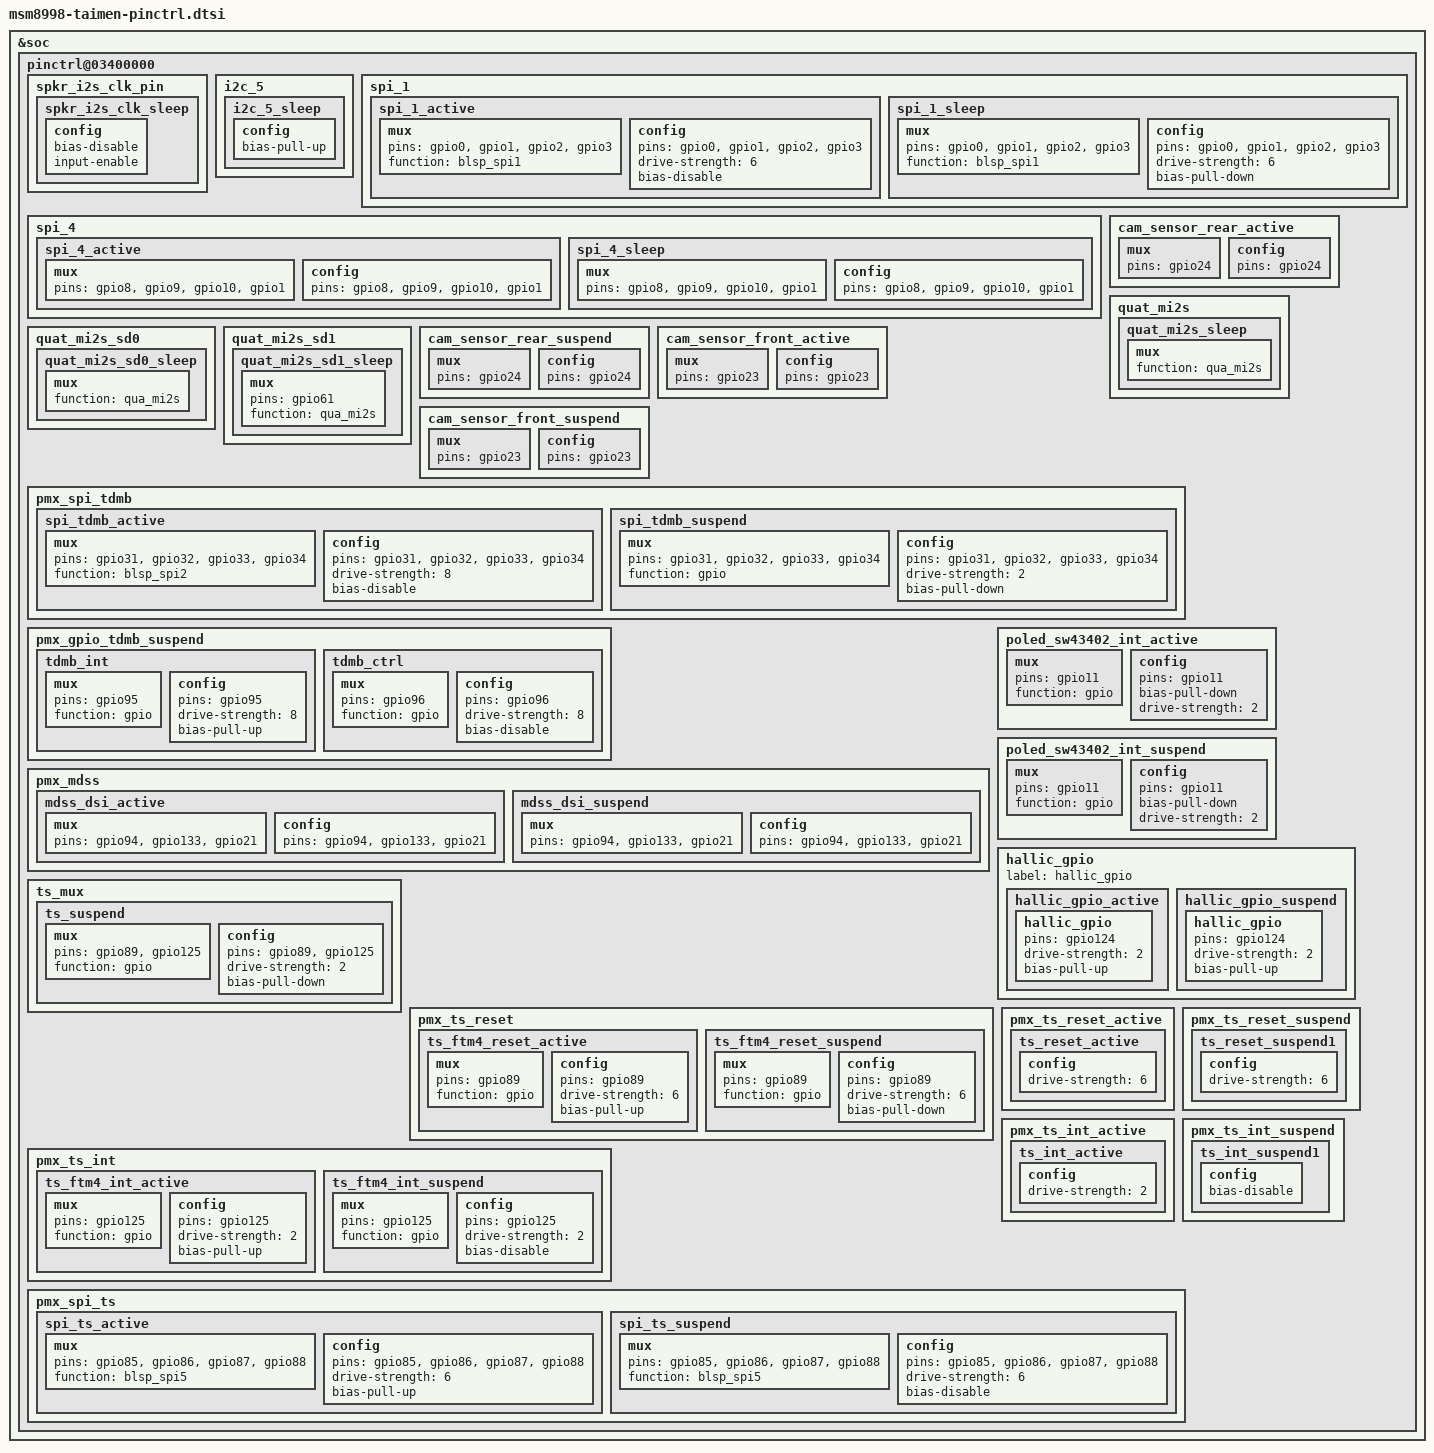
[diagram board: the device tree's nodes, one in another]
/* Copyright (c) 2017, The Linux Foundation. All rights reserved.
 *
 * This program is free software; you can redistribute it and/or modify
 * it under the terms of the GNU General Public License version 2 and
 * only version 2 as published by the Free Software Foundation.
 *
 * This program is distributed in the hope that it will be useful,
 * but WITHOUT ANY WARRANTY; without even the implied warranty of
 * MERCHANTABILITY or FITNESS FOR A PARTICULAR PURPOSE.  See the
 * GNU General Public License for more details.
 */

&soc {
	pinctrl@03400000 {
		spkr_i2s_clk_pin {
			spkr_i2s_clk_sleep {
				config {
					bias-disable;
					input-enable;
				};
			};
		};

		i2c_5 {
			i2c_5_sleep {
				config {
					bias-pull-up;
				};
			};
		};

		/* SPI CONFIGURATION */

		spi_1 {
			spi_1_active {
				mux {
					pins = "gpio0", "gpio1",
							"gpio2", "gpio3";
					function = "blsp_spi1";
				};

				config {
					pins = "gpio0", "gpio1",
							"gpio2", "gpio3";
					drive-strength = <6>;
					bias-disable;
				};
			};

			spi_1_sleep {
				mux {
					pins = "gpio0", "gpio1",
							"gpio2", "gpio3";
					function = "blsp_spi1";
				};

				config {
					pins = "gpio0", "gpio1",
							"gpio2", "gpio3";
					drive-strength = <6>;
					bias-pull-down;
				};
			};
		};

		spi_4 {
			spi_4_active {
				mux {
					pins = "gpio8", "gpio9",
							"gpio10", "gpio1";
				};

				config {
					pins = "gpio8", "gpio9",
							"gpio10", "gpio1";
				};
			};

			spi_4_sleep {
				mux {
					pins = "gpio8", "gpio9",
							"gpio10", "gpio1";
				};

				config {
					pins = "gpio8", "gpio9",
							"gpio10", "gpio1";
				};
			};
		};

		cam_sensor_rear_active {
			/* RESET, STANDBY */
			mux {
				pins = "gpio24";
			};

			config {
				pins = "gpio24";
			};
		};

		/* tas2557s MI2S Setting */
		quat_mi2s {
			quat_mi2s_sleep {
				mux {
					function = "qua_mi2s";
				};
			};
		};

		quat_mi2s_sd0 {
			quat_mi2s_sd0_sleep {
				mux {
					function = "qua_mi2s";
				};
			};
		};

		quat_mi2s_sd1 {
			quat_mi2s_sd1_sleep {
				mux {
					pins = "gpio61";
					function = "qua_mi2s";
				};
			};
		};

		cam_sensor_rear_suspend {
			/* RESET, STANDBY */
			mux {
				pins = "gpio24";
			};

			config {
				pins = "gpio24";
			};
		};

		cam_sensor_front_active {
			/* RESET */
			mux {
				pins = "gpio23";
			};

			config {
				pins = "gpio23";
			};
		};

		cam_sensor_front_suspend {
			/* RESET */
			mux {
				pins = "gpio23";
			};

			config {
				pins = "gpio23";
			};
		};

		pmx_spi_tdmb {
			spi_tdmb_active {
				mux {
					pins =  "gpio31", "gpio32", "gpio33", "gpio34";
					function = "blsp_spi2";
				};

				config {
					pins =  "gpio31", "gpio32", "gpio33", "gpio34";
					drive-strength = <8>;
					bias-disable;
				};
			};

			spi_tdmb_suspend {
				mux {
					pins =  "gpio31", "gpio32", "gpio33", "gpio34";
					function = "gpio";
				};

				config {
					pins =  "gpio31", "gpio32", "gpio33", "gpio34";
					drive-strength = <2>;
					bias-pull-down;
				};
			};
		};

		pmx_gpio_tdmb_suspend {
			tdmb_int {
				mux {
					pins = "gpio95";
					function = "gpio";
				};
				config {
					pins = "gpio95";
					drive-strength = <8>;
					bias-pull-up;
				};
			};
			tdmb_ctrl {
				mux {
					pins = "gpio96";
					function = "gpio";
				};
				config {
					pins = "gpio96";
					drive-strength = <8>;
					bias-disable;
				};
			};
		};

		pmx_mdss {
			mdss_dsi_active {
				mux {
					pins = "gpio94", "gpio133", "gpio21";
				};

				config {
					pins = "gpio94", "gpio133", "gpio21";
				};
			};
			mdss_dsi_suspend {
				mux {
					pins = "gpio94", "gpio133", "gpio21";
				};

				config {
					pins = "gpio94", "gpio133", "gpio21";
				};
			};
		};
		poled_sw43402_int_active {
			mux {
				pins = "gpio11";
				function = "gpio";
			};

			config {
				pins = "gpio11";
				bias-pull-down;
				drive-strength = <2>;
			};
		};

		poled_sw43402_int_suspend {
			mux {
				pins = "gpio11";
				function = "gpio";
			};

			config {
				pins = "gpio11";
				bias-pull-down;
				drive-strength = <2>;
			};
		};

		/* pin set for Hall IC */
		hallic_gpio {
			label = "hallic_gpio";
			hallic_gpio_active: hallic_gpio_active {
				hallic_gpio {
					pins = "gpio124";
					drive-strength = <2>;
					bias-pull-up;
				};
			};
			hallic_gpio_suspend: hallic_gpio_suspend {
				hallic_gpio {
					pins = "gpio124";
					drive-strength = <2>;
					bias-pull-up;
				};
			};
		};

		ts_mux {
			ts_suspend: ts_suspend {
				mux {
					pins = "gpio89", "gpio125";
					function = "gpio";
				};

				config {
					pins = "gpio89", "gpio125";
					drive-strength = <2>;
					bias-pull-down;
				};
			};
		};

		pmx_ts_reset {
			ts_ftm4_reset_active {
				mux {
					pins = "gpio89";
					function = "gpio";
				};
				config {
					pins = "gpio89";
					drive-strength = <6>;
					bias-pull-up;
				};
			};

			ts_ftm4_reset_suspend {
				mux {
					pins = "gpio89";
					function = "gpio";
				};
				config {
					pins = "gpio89";
					drive-strength = <6>;
					bias-pull-down;
				};
			};
		};

		pmx_ts_int {
			ts_ftm4_int_active {
				mux {
					pins = "gpio125";
					function = "gpio";
				};
				config {
					pins = "gpio125";
					drive-strength = <2>;
					bias-pull-up;
				};
			};

			ts_ftm4_int_suspend {
				mux {
					pins = "gpio125";
					function = "gpio";
				};
				config {
					pins = "gpio125";
					drive-strength = <2>;
					bias-disable;
				};
			};
		};

		pmx_ts_reset_active {
			ts_reset_active {
				config {
					drive-strength = <6>;
				};
			};
		};

		pmx_ts_reset_suspend {
			ts_reset_suspend1 {
				config {
					drive-strength = <6>;
				};
			};
		};

		pmx_ts_int_active {
			ts_int_active {
				config {
					drive-strength = <2>;
				};
			};
		};

		pmx_ts_int_suspend {
			ts_int_suspend1 {
				config {
					bias-disable;
				};
			};
		};

		pmx_spi_ts {
			spi_ts_active: spi_ts_active {
			/* TOUCH MOSI, MISO */
				mux {
					pins = "gpio85", "gpio86",
							"gpio87", "gpio88";
					function = "blsp_spi5";
				};
				config {
					pins = "gpio85", "gpio86",
							"gpio87", "gpio88";
					drive-strength = <6>; /* 8MA */
					bias-pull-up;
				};
			};

			spi_ts_suspend: spi_ts_suspend {
			/* TOUCH MOSI, MISO */
				mux {
					pins = "gpio85", "gpio86",
							"gpio87", "gpio88";
					function = "blsp_spi5";
				};
				config {
					pins = "gpio85", "gpio86",
							"gpio87", "gpio88";
					drive-strength = <6>; /* 2MA */
					bias-disable; /* No PULL */
				};
			};
		};
	};
};
